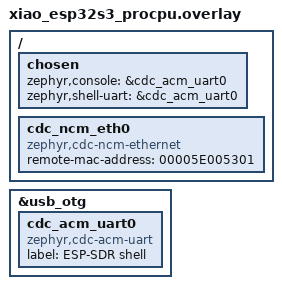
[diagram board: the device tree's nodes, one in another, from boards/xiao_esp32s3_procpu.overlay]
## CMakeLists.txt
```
# SPDX-License-Identifier: GPL-3.0-or-later

cmake_minimum_required(VERSION 3.20.0)

find_package(Zephyr REQUIRED HINTS $ENV{ZEPHYR_BASE})
project(esp_stream)

include(${CMAKE_CURRENT_LIST_DIR}/../common/common.cmake)

target_sources(app PRIVATE
  src/main.c
  src/vrt_rx.c
  src/iq_pack.c)
target_sources_ifdef(CONFIG_SHELL app PRIVATE src/shell.c)
target_sources_ifdef(CONFIG_APP_TX app PRIVATE src/vrt_tx.c)

if(CONFIG_USBD_CDC_NCM_CLASS)
  target_sources(app PRIVATE src/transport_udp.c)
else()
  target_sources(app PRIVATE src/transport_null.c)
endif()
# Per-sample loops on the stream's critical path.
set_source_files_properties(src/iq_pack.c PROPERTIES COMPILE_OPTIONS -O3)
```

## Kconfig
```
# SPDX-License-Identifier: GPL-3.0-or-later

mainmenu "ESP-SDR stream"

config APP_SDR
	bool "Run the radio"
	default y
	help
	  Disable to bring up USB and the network alone: the app then sends
	  one small test datagram per second instead of capturing.

config APP_FREQ_MHZ
	int "LO frequency in MHz at boot (shared by RX and TX)"
	range 100 6000
	default 2412

config APP_RX_RATE
	int "Capture rate (enum esp_sdr_rate index)"
	range 0 6
	default 6
	help
	  0: 80 MS/s, 1: 40 MS/s, 6: 16 MS/s. A VITA command can switch to
	  this rate divided by an integer (decimated stream).

config APP_RX_BURST_SAMPLES
	int "Complex samples per burst"
	range 256 16380
	default 1404
	help
	  Raw bursts at the capture rate, and the most a decimated burst may
	  hold. 1404 fills whole signal data packets at every item size: 3 at
	  12 bit (468 each), 2 at 8 bit (704), 4 at 16 bit (352). USB moves a
	  limited number of datagrams per second, so a part-filled packet costs
	  as much as a full one.

config APP_RX_BURSTS
	int "Burst buffers between the capture and process cores"
	default 3
	help
	  Each holds APP_RX_BURST_SAMPLES * 4 bytes, in the internal SRAM
	  above the capture bank (ESP_SDR_HIGH_RAM).

config APP_NET_CPU
	int "CPU for the network and USB threads (-1: not pinned)"
	range -1 1
	default 0
	help
	  Pins the cooperative and high priority system threads (net TX/RX
	  queues, net_mgmt, usbd, UDC, system work queue, Wi-Fi events) to
	  this CPU, the capture CPU, so they never delay the process thread or
	  the DAC leader on the other one.

config APP_RX_BURST_INTERVAL_MS
	int "Pause between bursts in ms (0: back to back)"
	default 0

config APP_RX_STREAM_ID
	hex "VITA 49 stream identifier of the receive stream"
	help
	  Command packets to this stream ID set the receiver; any other
	  stream ID addresses the transmitter.
	default 0x5d5d0001

config APP_RX_SAMPLES_PER_PACKET
	int "Complex samples per IF data packet"
	range 1 1000
	default 352
	help
	  352 samples plus six header and trailer words fit a 1500 byte
	  IPv6 UDP datagram.

config APP_RX_UDP_PEER
	string "IPv6 destination of the receive stream"
	default "ff02::1"
	help
	  The default link-local all-nodes group reaches the host without
	  any address setup on either side.

config APP_RX_UDP_PORT
	int "UDP destination port of the receive stream"
	default 4991

config APP_TX
	bool "Transmit VITA 49.2 signal data from the host"
	default y
	select ESP_SDR_TX
	help
	  Signal data and command packets on UDP; samples go to the
	  esp_sdr_tx streaming backend (the DAC backend with
	  CONFIG_ESP_SDR_TX_DAC, else the stub).

config APP_TX_UDP_PORT
	int "UDP port for transmit and command packets"
	default 4992
	depends on APP_TX

config APP_TX_RATE
	int "Transmit sample rate until a command sets one"
	default 100000
	depends on APP_TX

rsource "../common/Kconfig"

# USB device helpers shared with the in-tree USB samples.
source "samples/subsys/usb/common/Kconfig.sample_usbd"

source "Kconfig.zephyr"
```

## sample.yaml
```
sample:
  name: ESP-SDR stream
  description: >-
    Burst I/Q capture on both cores, VITA 49.2 packets as UDP over IPv6 on a
    USB CDC-NCM link, USB DFU through MCUboot, Zephyr shell on USB CDC-ACM
common:
  tags: esp-sdr
  sysbuild: true
  platform_allow:
    - xiao_esp32s3/esp32s3/procpu
  integration_platforms:
    - xiao_esp32s3/esp32s3/procpu
tests:
  # The console is on USB CDC-ACM, which twister cannot reach over
  # USB-Serial-JTAG: run it with tools/vrt_rx.py instead (see README).
  sample.esp_sdr.stream:
    build_only: true
```

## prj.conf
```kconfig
# The Wi-Fi driver brings the radio up at boot; nothing may scan or connect.
CONFIG_NETWORKING=y
CONFIG_WIFI=y
CONFIG_ESP32_WIFI_STA_POWER_SAVE_NONE=y

CONFIG_ESP_SDR=y
# Deferred logging: immediate mode formats on the caller's stack, which
# overflows the small USB driver thread stacks.
CONFIG_LOG=y
CONFIG_LOG_MODE_DEFERRED=y

# Float statistics on the process thread.
CONFIG_FPU=y
CONFIG_FPU_SHARING=y
CONFIG_PICOLIBC_IO_FLOAT=y
CONFIG_MAIN_STACK_SIZE=2048

# Capture on CPU 0 next to the Wi-Fi task, process on CPU 1.
CONFIG_SMP=y

CONFIG_LIBVRT=y

# USB device on the OTG port (DFU with sysbuild/MCUboot).
CONFIG_USB_DEVICE_STACK_NEXT=y
CONFIG_SAMPLE_USBD_PRODUCT="ESP-SDR"
CONFIG_SAMPLE_USBD_PID=0x0005
CONFIG_USBD_LOG_LEVEL_WRN=y
CONFIG_UDC_DRIVER_LOG_LEVEL_WRN=y
CONFIG_USBD_THREAD_STACK_SIZE=2048
CONFIG_UDC_DWC2_STACK_SIZE=1280

# USB network (CDC-NCM) carrying the VRT stream as UDP over IPv6.
CONFIG_USBD_CDC_NCM_CLASS=y
# Room for 5 full datagrams per OUT NTB: the host aggregates them into one
# transfer (USB full speed moves a limited number of transfers per second).
CONFIG_USBD_CDC_NCM_RECV_NTB_MAX_SIZE=8192
CONFIG_USBD_CDC_NCM_MAX_DGRAM_PER_NTB=5
# Uplink: up to 3 datagrams per IN NTB, collected while one is in flight.
CONFIG_USBD_CDC_NCM_SEND_NTB_MAX_SIZE=4608
CONFIG_USBD_CDC_NCM_SEND_MAX_DGRAM_PER_NTB=3
CONFIG_NET_IPV6=y
CONFIG_NET_IPV4=n
CONFIG_NET_UDP=y
CONFIG_NET_SOCKETS=y
# Receive timeout for the transmit socket (idle stop).
CONFIG_NET_CONTEXT_RCVTIMEO=y
CONFIG_NET_IF_MAX_IPV6_COUNT=2
CONFIG_NET_BUF_DATA_SIZE=256
CONFIG_NET_PKT_TX_COUNT=24
CONFIG_NET_BUF_TX_COUNT=32
# Receive buffers for the host's transmit stream (1500 byte datagrams).
CONFIG_NET_PKT_RX_COUNT=16
CONFIG_NET_BUF_RX_COUNT=48
# "net stats" in the shell.
CONFIG_NET_STATISTICS=y
CONFIG_NET_STATISTICS_PER_INTERFACE=y

# Console and Zephyr shell on a USB CDC-ACM port; the shell log backend
# carries the logs, so the UART backend would only duplicate them.
CONFIG_USBD_CDC_ACM_CLASS=y
# CDC-ACM carries the console and the shell: its own logging must stay off (it would log to
# itself), which usbd_cdc_acm.c otherwise enforces with a #warning that -Werror makes fatal.
CONFIG_USBD_CDC_ACM_LOG_LEVEL_OFF=y
CONFIG_CDC_ACM_SERIAL_INITIALIZE_AT_BOOT=n
CONFIG_SHELL=y
CONFIG_KERNEL_SHELL=y
CONFIG_NET_SHELL=y
CONFIG_LOG_BACKEND_UART=n
# Lean shell: net, kernel and mcuboot commands only.
CONFIG_SHELL_STACK_SIZE=3072
CONFIG_SHELL_CMD_BUFF_SIZE=128
CONFIG_SHELL_HISTORY=n
CONFIG_SHELL_WILDCARD=n
CONFIG_SHELL_BACKEND_SERIAL_LOG_MESSAGE_QUEUE_SIZE=256
CONFIG_DEVICE_SHELL=n
CONFIG_DATE_SHELL=n
CONFIG_DEVMEM_SHELL=n
# Wi-Fi management commands would also retune the radio under the receiver.
CONFIG_NET_L2_WIFI_SHELL=n

# 8 MB octal PSRAM: transmit waveform ring (EXT_RAM_BSS_ATTR).
CONFIG_ESP_SPIRAM=y
CONFIG_SPIRAM_MODE_OCT=y

# Heap statistics for `sdr mem` (sizing internal RAM).
CONFIG_SYS_HEAP_RUNTIME_STATS=y

# Internal RAM diet: two 64 KiB dump banks must fit (capture and DAC ping-pong).
# Sizes from `sdr mem` and `kernel thread stacks` after a TX and RX run.
CONFIG_ESP_WIFI_HEAP_SPIRAM=y
CONFIG_ESP32_WIFI_STATIC_RX_BUFFER_NUM=4
CONFIG_ESP32_WIFI_MGMT_SBUF_NUM=8
CONFIG_ESP32_WIFI_EVENT_TASK_STACK_SIZE=1024
CONFIG_NET_MGMT_EVENT_STACK_SIZE=1024
CONFIG_APP_RX_BURSTS=2
CONFIG_ESP_SDR_TX_DAC_STACK_SIZE=1024
# Internal system heap: peak 15.5 KB measured with the Wi-Fi heap in PSRAM.
CONFIG_HEAP_MEM_POOL_IGNORE_MIN=y
CONFIG_HEAP_MEM_POOL_SIZE=20480
```

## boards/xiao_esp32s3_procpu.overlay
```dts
/*
 * SPDX-License-Identifier: GPL-3.0-or-later
 */

/ {
	chosen {
		zephyr,console = &cdc_acm_uart0;
		zephyr,shell-uart = &cdc_acm_uart0;
	};

	/* USB network function; the host side of the link gets MAC 00:00:5e:00:53:01. */
	cdc_ncm_eth0: cdc_ncm_eth0 {
		compatible = "zephyr,cdc-ncm-ethernet";
		remote-mac-address = "00005E005301";
	};
};

zephyr_udc0: &usb_otg {
	status = "okay";

	/* Console, shell and logs while OTG owns the USB port. */
	cdc_acm_uart0: cdc_acm_uart0 {
		compatible = "zephyr,cdc-acm-uart";
		label = "ESP-SDR shell";
	};
};
```

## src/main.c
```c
/*
 * SPDX-License-Identifier: GPL-3.0-or-later
 *
 * Burst I/Q pipeline across both cores: CPU 0 captures, CPU 1 processes.
 */

#include <math.h>
#include <string.h>

#include <zephyr/app_version.h>
#include <zephyr/kernel.h>
#include <zephyr/logging/log.h>
#include <zephyr/sys/util.h>

#include <esp_sdr/esp_sdr.h>

#include "vrt_rx.h"
#include "transport.h"
#include "vrt_tx.h"
#include "app_cpu.h"
#include "app_usb.h"

LOG_MODULE_REGISTER(stream, LOG_LEVEL_INF);

#define CAPTURE_CPU 0
#define PROCESS_CPU 1
#define CAPTURE_STACK_SIZE 2048
#define PROCESS_STACK_SIZE 3072

/* Bursts live above the capture bank: frees low DRAM for the USB buffers. */
K_MEM_SLAB_DEFINE_IN_SECT(burst_slab, Z_GENERIC_SECTION(.esp_sdr_high), sizeof(struct vrt_rx_burst),
			  CONFIG_APP_RX_BURSTS, 4);
K_MSGQ_DEFINE(burst_q, sizeof(struct vrt_rx_burst *), CONFIG_APP_RX_BURSTS, 4);

K_THREAD_STACK_DEFINE(capture_stack, CAPTURE_STACK_SIZE);
K_THREAD_STACK_DEFINE(process_stack, PROCESS_STACK_SIZE);
static struct k_thread capture_thread, process_thread;

static atomic_t capture_cpu = ATOMIC_INIT(-1), process_cpu = ATOMIC_INIT(-1);
static atomic_t stalls;
/* Decimation factor, 1 = raw bursts at the capture rate. */
static atomic_t rx_decim = ATOMIC_INIT(1);
/* Algorithm used when rx_decim > 1. */
static atomic_t rx_mode = ATOMIC_INIT(VRT_RX_DECIM_CIC);

/* Decimated bursts must fit the burst buffer. */
BUILD_ASSERT(ESP_SDR_SAMPLES_MAX / VRT_RX_DECIM_MIN <= CONFIG_APP_RX_BURST_SAMPLES + 3U);
BUILD_ASSERT(sizeof(struct esp_sdr_iq16) == sizeof(struct esp_sdr_iq16));

int vrt_rx_set_rate(uint32_t hz)
{
	uint32_t fs = esp_sdr_rx_rate_hz(CONFIG_APP_RX_RATE), m;

	if (hz == 0U || fs % hz != 0U) {
		return -EINVAL;
	}
	m = fs / hz;
	if (m != 1U && (m < VRT_RX_DECIM_MIN || m > ESP_SDR_RX_DECIM_MAX)) {
		return -EINVAL;
	}
	atomic_set(&rx_decim, (atomic_val_t)m);
	return 0;
}

uint32_t vrt_rx_get_rate(void)
{
	return esp_sdr_rx_rate_hz(CONFIG_APP_RX_RATE) / (uint32_t)atomic_get(&rx_decim);
}

int vrt_rx_set_decim(enum vrt_rx_decim mode)
{
	if (mode != VRT_RX_DECIM_CIC && mode != VRT_RX_DECIM_FOLD) {
		return -EINVAL;
	}
	atomic_set(&rx_mode, (atomic_val_t)mode);
	return 0;
}

enum vrt_rx_decim vrt_rx_get_decim(void)
{
	return (enum vrt_rx_decim)atomic_get(&rx_mode);
}

static void capture(void *p1, void *p2, void *p3)
{
	enum esp_sdr_rate rate = CONFIG_APP_RX_RATE;
	uint32_t seq = 0;
	int ret;

	ARG_UNUSED(p1);
	ARG_UNUSED(p2);
	ARG_UNUSED(p3);

	ret = esp_sdr_init();
	if (ret == 0) {
		ret = esp_sdr_set_freq(CONFIG_APP_FREQ_MHZ);
	}
	if (ret != 0) {
		LOG_ERR("radio setup failed (%d)", ret);
		return;
	}

	for (;;) {
		struct vrt_rx_burst *b;

		if (k_mem_slab_alloc(&burst_slab, (void **)&b, K_NO_WAIT) != 0) {
			/* Process side is behind: wait, which also lets it run on one CPU. */
			atomic_inc(&stalls);
			(void)k_mem_slab_alloc(&burst_slab, (void **)&b, K_FOREVER);
		}
		uint32_t m = (uint32_t)atomic_get(&rx_decim);

		if (m > 1U) {
			/* Whole bank, decimated on the capture core while it still holds the bank. */
			enum vrt_rx_decim mode = (enum vrt_rx_decim)atomic_get(&rx_mode);
			size_t n;
			uint64_t first;

			if (mode == VRT_RX_DECIM_FOLD) {
				ret = esp_sdr_rx_capture_folded(rate, ESP_SDR_SAMPLES_MAX / m * m,
								 m, (struct esp_sdr_iq16 *)b->iq,
								 ARRAY_SIZE(b->iq), &n, &first);
				b->full_scale = 512;
			} else {
				ret = esp_sdr_rx_capture_decimated(rate, ESP_SDR_SAMPLES_MAX / m * m,
								    m, (struct esp_sdr_iq16 *)b->iq,
								    ARRAY_SIZE(b->iq), &n, &first);
				b->full_scale = 32768;
			}
			b->count = n;
			b->timestamp_ns = first;
			b->rate_hz = esp_sdr_rx_rate_hz(rate) / m;
		} else {
			uint64_t first;

			/* Converted under the radio lock: a TX session reuses the bank. */
			ret = esp_sdr_rx_capture_iq(rate, CONFIG_APP_RX_BURST_SAMPLES,
						    (struct esp_sdr_iq16 *)b->iq, &first);
			if (ret == 0) {
				b->count = CONFIG_APP_RX_BURST_SAMPLES;
				/* The engine starts on the trigger: arming time is the first sample. */
				b->timestamp_ns = first;
				b->rate_hz = esp_sdr_rx_rate_hz(rate);
				b->full_scale = 512;
			}
		}
		if (ret != 0) {
			LOG_WRN("capture failed (%d)", ret);
			k_mem_slab_free(&burst_slab, b);
			k_sleep(K_MSEC(100));
			continue;
		}
		b->seq = seq++;
		b->freq_mhz = esp_sdr_get_freq();
		b->gain = esp_sdr_rx_get_gain();
		atomic_set(&capture_cpu, arch_curr_cpu()->id);
		k_msgq_put(&burst_q, &b, K_FOREVER);

		if (CONFIG_APP_RX_BURST_INTERVAL_MS > 0) {
			k_sleep(K_MSEC(CONFIG_APP_RX_BURST_INTERVAL_MS));
		}
	}
}


static void process(void *p1, void *p2, void *p3)
{
	uint32_t bursts = 0, samples = 0;
	int64_t window_start = k_uptime_get();
	float power = 0.0f;

	ARG_UNUSED(p1);
	ARG_UNUSED(p2);
	ARG_UNUSED(p3);

	for (;;) {
		struct vrt_rx_burst *b;
		uint64_t sum = 0;
		int64_t now;

		k_msgq_get(&burst_q, &b, K_FOREVER);
		atomic_set(&process_cpu, arch_curr_cpu()->id);

		/* Integer energy: at most 2 * 32768^2 per sample, fits 32 bits unsigned. */
		for (size_t j = 0; j < b->count; j++) {
			int32_t i = b->iq[j].i, q = b->iq[j].q;

			sum += (uint32_t)(i * i) + (uint32_t)(q * q);
		}
		power = (float)sum / (float)b->count /
			((float)b->full_scale * (float)b->full_scale);
		vrt_rx_burst(b);
		bursts++;
		samples += b->count;
		k_mem_slab_free(&burst_slab, b);

		now = k_uptime_get();
		if (now - window_start >= 1000) {
			float secs = (float)(now - window_start) / 1000.0f;

			LOG_DBG("capture cpu %ld, process cpu %ld, %u bursts/s, "
				"%.2f MS/s, %.1f dBFS, stalls %ld",
				atomic_get(&capture_cpu), atomic_get(&process_cpu),
				(unsigned int)((float)bursts / secs),
				(double)((float)samples / secs / 1e6f),
				(double)(10.0f * log10f(MAX(power, 1e-12f))), atomic_get(&stalls));
			vrt_rx_report();
			bursts = 0;
			samples = 0;
			window_start = now;
		}
	}
}

int main(void)
{
	printk("stream %s\n", APP_VERSION_STRING);
	LOG_INF("cpus %u, %u MHz, %u-sample bursts", arch_num_cpus(), CONFIG_APP_FREQ_MHZ,
		CONFIG_APP_RX_BURST_SAMPLES);

#if defined(CONFIG_SCHED_CPU_MASK) && CONFIG_APP_NET_CPU >= 0
	/*
	 * Before USB starts: its bring-up runs on the system work queue, and
	 * the controller interrupt lands on the CPU that allocates it.
	 */
	if (arch_num_cpus() > 1) {
		app_cpu_pin_system_threads(CONFIG_APP_NET_CPU);
	}
#endif
	if (app_usb_init() != 0) {
		LOG_ERR("usb init failed");
	}
	if (vrt_rx_init() != 0) {
		LOG_ERR("stream init failed");
		return 0;
	}
	if (IS_ENABLED(CONFIG_APP_TX) && vrt_tx_init() != 0) {
		LOG_ERR("tx init failed");
	}

	if (!IS_ENABLED(CONFIG_APP_SDR)) {
		/* USB bring-up test: a small datagram per second instead of samples. */
		static const char beacon[] = "rx stream: beacon\n";

		for (;;) {
			(void)transport_send(beacon, sizeof(beacon) - 1);
			k_sleep(K_SECONDS(1));
		}
	}

	k_thread_create(&capture_thread, capture_stack, K_THREAD_STACK_SIZEOF(capture_stack),
			capture, NULL, NULL, NULL, K_PRIO_PREEMPT(5), 0, K_FOREVER);
	k_thread_create(&process_thread, process_stack, K_THREAD_STACK_SIZEOF(process_stack),
			process, NULL, NULL, NULL, K_PRIO_PREEMPT(6), 0, K_FOREVER);
	k_thread_name_set(&capture_thread, "rx_capture");
	k_thread_name_set(&process_thread, "rx_process");
#if defined(CONFIG_SCHED_CPU_MASK)
	if (arch_num_cpus() > 1) {
		k_thread_cpu_pin(&capture_thread, CAPTURE_CPU);
		k_thread_cpu_pin(&process_thread, PROCESS_CPU);
#if CONFIG_APP_NET_CPU >= 0
		/* Again for the threads started since (usbd, UDC). */
		app_cpu_pin_system_threads(CONFIG_APP_NET_CPU);
#endif
	}
#endif
	k_thread_start(&capture_thread);
	k_thread_start(&process_thread);
	return 0;
}
```

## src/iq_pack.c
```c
/*
 * SPDX-License-Identifier: GPL-3.0-or-later
 */

#include <zephyr/sys/util.h>

#include "iq_pack.h"

size_t iq_samples_per_words(unsigned int bits, size_t max_words)
{
	size_t n = max_words * 32U / (2U * bits);

	return n - n % iq_sample_quantum(bits);
}

/* Item of `bits` from a sample: scaled by 2^-shift (rounded) or 2^shift, saturated. */
static inline uint32_t item(int32_t x, int32_t shift, int32_t lim, uint32_t mask)
{
	if (shift > 0) {
		x = (x + (1 << (shift - 1))) >> shift;
	} else {
		x <<= -shift;
	}
	return (uint32_t)CLAMP(x, -lim, lim - 1) & mask;
}

size_t iq_pack(const struct esp_sdr_iq16 *s, size_t n, unsigned int bits, int32_t full_scale,
	       uint32_t *words)
{
	int32_t lim = 1 << (bits - 1U);
	uint32_t mask = (1U << bits) - 1U;
	/* full_scale is a power of two: 512 (raw) or 32768 (decimated). */
	int32_t shift = (int32_t)(31 - __builtin_clz((uint32_t)full_scale)) - (int32_t)(bits - 1U);
	uint64_t acc = 0;
	unsigned int have = 0;
	size_t w = 0, j = 0;

	if (bits == 16U) {
		/* Legacy layout: native scale, I in the upper half word. */
		for (; j < n; j++) {
			words[j] = ((uint32_t)(uint16_t)s[j].i << 16) | (uint16_t)s[j].q;
		}
		return n;
	}
	if (bits == 8U) {
		/* Two samples per word. */
		for (; j + 2U <= n; j += 2U) {
			words[w++] = item(s[j].i, shift, lim, mask) << 24 |
				     item(s[j].q, shift, lim, mask) << 16 |
				     item(s[j + 1U].i, shift, lim, mask) << 8 |
				     item(s[j + 1U].q, shift, lim, mask);
		}
	} else if (bits == 12U) {
		/* Four samples, eight items, in three words. */
		for (; j + 4U <= n; j += 4U) {
			uint32_t a = item(s[j].i, shift, lim, mask), b = item(s[j].q, shift, lim, mask);
			uint32_t c = item(s[j + 1U].i, shift, lim, mask);
			uint32_t d = item(s[j + 1U].q, shift, lim, mask);
			uint32_t e = item(s[j + 2U].i, shift, lim, mask);
			uint32_t f = item(s[j + 2U].q, shift, lim, mask);
			uint32_t g = item(s[j + 3U].i, shift, lim, mask);
			uint32_t h = item(s[j + 3U].q, shift, lim, mask);

			words[w++] = a << 20 | b << 8 | c >> 4;
			words[w++] = c << 28 | d << 16 | e << 4 | f >> 8;
			words[w++] = f << 24 | g << 12 | h;
		}
	}
	/* Whatever is left (none in whole quanta), MSB first. */
	for (; j < n; j++) {
		acc = (acc << (2U * bits)) | ((uint64_t)item(s[j].i, shift, lim, mask) << bits) |
		      item(s[j].q, shift, lim, mask);
		have += 2U * bits;
		while (have >= 32U) {
			have -= 32U;
			words[w++] = (uint32_t)(acc >> have);
		}
	}
	if (have > 0U) {
		/* Left aligned, zero padded (less than one item thanks to the quantum). */
		words[w++] = (uint32_t)(acc << (32U - have));
	}
	return w;
}

size_t iq_unpack(const uint32_t *words, size_t nwords, unsigned int bits, int16_t *iq,
		 size_t max)
{
	uint64_t acc = 0;
	unsigned int have = 0;
	size_t n = 0;

	if (bits == 16U) {
		for (; n < nwords && n < max; n++) {
			iq[2U * n] = (int16_t)(words[n] >> 16);
			iq[2U * n + 1U] = (int16_t)(words[n] & 0xffffU);
		}
		return n;
	}
	for (size_t k = 0; k < nwords && n < max; k++) {
		acc = (acc << 32) | words[k];
		have += 32U;
		while (have >= 2U * bits && n < max) {
			uint32_t pair = (uint32_t)(acc >> (have - 2U * bits));

			have -= 2U * bits;
			/* Item to the top of 32 bits (sign there), down 16: int16 full scale. */
			iq[2U * n] = (int16_t)((int32_t)((pair >> bits) << (32U - bits)) >> 16);
			iq[2U * n + 1U] = (int16_t)((int32_t)(pair << (32U - bits)) >> 16);
			n++;
		}
	}
	return n;
}
```

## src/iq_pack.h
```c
/*
 * SPDX-License-Identifier: GPL-3.0-or-later
 *
 * VITA 49 link-efficient complex payloads: I then Q per sample, 8, 12 or 16
 * bits per item, packed MSB first across 32-bit words (CPU order; the stream
 * code swaps to network order).
 */

#ifndef STREAM_IQ_PACK_H_
#define STREAM_IQ_PACK_H_

#include <stddef.h>
#include <stdint.h>

#include "vrt_rx.h"

/* Supported item sizes. */
static inline int iq_bits_valid(unsigned int bits)
{
	return bits == 8U || bits == 12U || bits == 16U;
}

/*
 * Samples per packet must fill whole words without a padding gap a whole item
 * wide, or the receiver would see a phantom sample: multiples of this.
 */
static inline size_t iq_sample_quantum(unsigned int bits)
{
	return bits == 12U ? 4U : bits == 8U ? 2U : 1U;
}

/* Most samples (a whole quantum) that fit max_words. */
size_t iq_samples_per_words(unsigned int bits, size_t max_words);

/*
 * Pack n samples into words. 16-bit items keep the stream's own scale (full
 * scale 512 raw, 32768 decimated); 8 and 12-bit items are scaled to their own
 * full scale (2^(bits-1)), rounded and saturated. Returns words written.
 */
size_t iq_pack(const struct esp_sdr_iq16 *s, size_t n, unsigned int bits, int32_t full_scale,
	       uint32_t *words);

/*
 * Unpack nwords into interleaved int16 I, Q (8 and 12-bit items shifted up to
 * full scale 32767, 16-bit items as they are); returns samples written, at
 * most max.
 */
size_t iq_unpack(const uint32_t *words, size_t nwords, unsigned int bits, int16_t *iq,
		 size_t max);

#endif /* STREAM_IQ_PACK_H_ */
```

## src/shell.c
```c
/*
 * SPDX-License-Identifier: GPL-3.0-or-later
 *
 * The "sdr" shell command: receiver and transmitter controls and tests. The
 * receive stream picks changes up per burst.
 */

#include <math.h>
#include <stdlib.h>
#include <string.h>

#include <zephyr/kernel.h>
#include <zephyr/shell/shell.h>
#include <zephyr/sys/sys_heap.h>

#include <esp_attr.h>

#include <esp_sdr/esp_sdr.h>

#include "vrt_rx.h"

#if defined(CONFIG_APP_TX)
#include <esp_sdr/esp_sdr_tx.h>

#include "vrt_tx.h"
#endif

extern struct k_heap _system_heap;

static int cmd_mem(const struct shell *sh, size_t argc, char **argv)
{
	struct sys_memory_stats st;

	ARG_UNUSED(argc);
	ARG_UNUSED(argv);
	if (sys_heap_runtime_stats_get(&_system_heap.heap, &st) != 0) {
		shell_error(sh, "no heap stats");
		return -EIO;
	}
	shell_print(sh, "system heap: %u allocated, %u free, %u peak",
		    (unsigned int)st.allocated_bytes, (unsigned int)st.free_bytes,
		    (unsigned int)st.max_allocated_bytes);
	return 0;
}

#if defined(CONFIG_APP_TX)


/*
 * Transmit synthesis. The DAC runs at its own rate (40 or 80 MS/s, never the
 * 16 MS/s the receiver uses), so every generator works in Hz and seconds and
 * converts with esp_sdr_tx_rate_hz(). One buffer serves all of them.
 */
#define TX_RATE        ESP_SDR_RATE_40MSPS
#define TX_BUF_SAMPLES 2048U /* 51 us at 40 MS/s; RAM below the capture bank is tight */
#define FM_TWO_PI      6.28318530717958647692
#define FM_TWO_PI_F    6.28318530717958647692f
/* PSRAM: only CPU copies read it, the DAC plays from the bank. */
static EXT_RAM_BSS_ATTR uint32_t tx_buf[TX_BUF_SAMPLES];

static enum esp_sdr_rate tx_rate_arg(size_t argc, char **argv, size_t idx)
{
	return argc > idx ? (enum esp_sdr_rate)strtol(argv[idx], NULL, 0) : TX_RATE;
}

static int cmd_fm(const struct shell *sh, size_t argc, char **argv)
{
	double fm_hz = strtod(argv[1], NULL);
	double dev_hz = strtod(argv[2], NULL);
	long amp = argc > 3 ? strtol(argv[3], NULL, 0) : 400;
	double fs = (double)esp_sdr_tx_rate_hz(TX_RATE);
	double phase = 0.0;
	int ret;

	if (amp <= 0 || amp > 511) {
		shell_error(sh, "amplitude must be 1..511");
		return -EINVAL;
	}

	/* Instantaneous offset dev_hz * sin(2 pi fm_hz t), integrated to phase. */
	for (size_t n = 0; n < TX_BUF_SAMPLES; n++) {
		double inst_hz = dev_hz * sin(FM_TWO_PI * fm_hz * (double)n / fs);

		phase += FM_TWO_PI * inst_hz / fs;
		tx_buf[n] = esp_sdr_tx_word((int16_t)lround((double)amp * cos(phase)),
					    (int16_t)lround((double)amp * sin(phase)));
	}

	ret = esp_sdr_tx_play(TX_RATE, tx_buf, TX_BUF_SAMPLES);
	if (ret != 0) {
		shell_error(sh, "play: %d", ret);
		return ret;
	}
	shell_print(sh, "played %u samples at %u MS/s, %u MHz, fm %.1f Hz dev %.1f Hz amp %ld",
		    TX_BUF_SAMPLES, (unsigned int)(fs / 1e6), esp_sdr_get_freq(), fm_hz, dev_hz,
		    amp);
	return 0;
}

/*
 * Period length for a seamless tone: the n in [MIN, TX_BUF_SAMPLES] whose
 * whole number of cycles comes closest to the requested frequency.
 */
static size_t tone_period(double req, double fs, long *cycles)
{
	size_t best_n = TX_BUF_SAMPLES;
	double best_err = INFINITY;

	for (size_t n = TX_BUF_SAMPLES; n >= ESP_SDR_SAMPLES_MIN; n--) {
		long c = lround(req * (double)n / fs);
		double err = fabs((double)c * fs / (double)n - req);

		if (err < best_err) {
			best_err = err;
			best_n = n;
			*cycles = c;
			if (err < 1.0) {
				break;
			}
		}
	}
	return best_n;
}

/*
 * Quick link check: a steady tone (no modulation) and a one-shot receiver
 * that reports average power and average frequency over a whole burst, with
 * no search loop. Use this before fsktx/fskrx to confirm TX actually
 * reaches the other board at a sane level and offset.
 */
static int cmd_tonetx(const struct shell *sh, size_t argc, char **argv)
{
	double req = argc > 1 ? strtod(argv[1], NULL) : 1000000.0;
	uint32_t ms = argc > 2 ? (uint32_t)strtoul(argv[2], NULL, 0) : 0U;
	long amp = argc > 3 ? strtol(argv[3], NULL, 0) : 511;
	enum esp_sdr_rate rate = tx_rate_arg(argc, argv, 4);
	double fs = (double)esp_sdr_tx_rate_hz(rate);
	uint32_t bursts = 0;
	long cycles = 0;
	size_t n;
	int ret;

	if (fs == 0.0) {
		shell_error(sh, "transmit rate index must be 0 (80 MS/s) or 1 (40 MS/s)");
		return -EINVAL;
	}
	if (amp <= 0 || amp > 511 || fabs(req) >= fs / 2.0) {
		shell_error(sh, "amplitude must be 1..511 and |hz| below %.0f", fs / 2.0);
		return -EINVAL;
	}
	n = tone_period(req, fs, &cycles);
	for (size_t k = 0; k < n; k++) {
		double phase = FM_TWO_PI * (double)cycles * (double)k / (double)n;

		tx_buf[k] = esp_sdr_tx_word((int16_t)lround((double)amp * cos(phase)),
					    (int16_t)lround((double)amp * sin(phase)));
	}
	ret = esp_sdr_tx_play_for(rate, tx_buf, n, ms, &bursts);
	if (ret != 0) {
		shell_error(sh, "play: %d", ret);
		return ret;
	}
	shell_print(sh,
		    "tonetx: %u MHz %+.0f Hz, %u MS/s, period %u, amp %ld, txgain %d, %u bursts in %u ms",
		    esp_sdr_get_freq(), (double)cycles * fs / (double)n, (unsigned int)(fs / 1e6),
		    (unsigned int)n, amp, esp_sdr_tx_get_gain(), bursts, ms);
	return 0;
}

static int cmd_sweep(const struct shell *sh, size_t argc, char **argv)
{
	float f0 = strtof(argv[1], NULL), f1 = strtof(argv[2], NULL);
	uint32_t ms = (uint32_t)strtoul(argv[3], NULL, 0);
	int amp = argc > 4 ? (int)strtol(argv[4], NULL, 0) : 256;
	enum esp_sdr_rate rate = tx_rate_arg(argc, argv, 5);
	struct esp_sdr_tx_sweep_stats st;
	int ret = esp_sdr_tx_sweep(rate, f0, f1, ms, amp, &st);
	double fs = (double)esp_sdr_tx_rate_hz(rate);

	if (ret != 0) {
		shell_error(sh, "sweep: %d (|hz| below rate/2, ms 1..%u, amp 1..511)", ret,
			    ESP_SDR_TX_PLAY_MAX_MS);
		return ret;
	}
	shell_print(sh,
		    "sweep: %+.0f -> %+.0f Hz in %u ms at %u MS/s, txgain %d, amp %d: %u segments, "
		    "%u samples, duty %.0f %%",
		    (double)f0, (double)f1, st.elapsed_ms, (unsigned int)(fs / 1e6),
		    esp_sdr_tx_get_gain(), amp, st.segments, st.samples,
		    100.0 * st.samples / fs / (st.elapsed_ms / 1e3));
	return 0;
}

static int cmd_tonerx(const struct shell *sh, size_t argc, char **argv)
{
	struct esp_sdr_rx_burst b;
	float fs = (float)esp_sdr_rx_rate_hz(ESP_SDR_RATE_16MSPS);
	float sum_sq = 0.0f, sum_delta = 0.0f;
	int ret;

	ARG_UNUSED(argc);
	ARG_UNUSED(argv);

	ret = esp_sdr_rx_capture(ESP_SDR_RATE_16MSPS, ESP_SDR_SAMPLES_MAX, &b);
	if (ret != 0) {
		shell_error(sh, "capture: %d", ret);
		return ret;
	}
	for (size_t n = 0; n < b.count; n++) {
		float i = (float)esp_sdr_rx_i(b.words[n]), q = (float)esp_sdr_rx_q(b.words[n]);

		sum_sq += i * i + q * q;
	}
	for (size_t n = 1; n < b.count; n++) {
		float i0 = (float)esp_sdr_rx_i(b.words[n - 1]), q0 = (float)esp_sdr_rx_q(b.words[n - 1]);
		float i1 = (float)esp_sdr_rx_i(b.words[n]), q1 = (float)esp_sdr_rx_q(b.words[n]);
		float cross = q1 * i0 - i1 * q0, dot = i1 * i0 + q1 * q0;

		sum_delta += atan2f(cross, dot);
	}

	float power_dbfs = 10.0f * log10f(MAX(sum_sq / (float)b.count / (512.0f * 512.0f), 1e-12f));
	float avg_freq = sum_delta / (float)(b.count - 1) * fs / (float)FM_TWO_PI;

	shell_print(sh, "tonerx: %u samples, %.1f dBFS, avg freq %+.0f Hz", (unsigned int)b.count,
		    (double)power_dbfs, (double)avg_freq);
	return 0;
}

/*
 * Minimal 2-FSK: one bit is FSK_BIT_US of a continuous-phase tone at
 * +-FSK_DEV_HZ from the tuned LO. Frame: 0xAA preamble byte (for bit-timing
 * search on receive), a length byte, then up to FSK_MAX_MSG message bytes,
 * all MSB first. No error correction and no CRC: this is a demo of the
 * modulation and of differential-phase demodulation, not a protocol.
 * The whole frame must fit tx_buf at the transmit rate, hence the short bits.
 */
#define FSK_BIT_US     2U  /* 500 kbit/s */
#define FSK_SPB        32U /* receive samples per bit: FSK_BIT_US at 16 MS/s */
#define FSK_DEV_HZ     200000.0f
#define FSK_PREAMBLE   0xAAU
#define FSK_MAX_MSG    3U
#define FSK_MAX_BITS   ((2U + FSK_MAX_MSG) * 8U)
#define FSK_SEARCH_STEP 8U
/* No shared clock between boards: keep capturing bursts for this long so an
 * independently, manually triggered sdr fsktx has a real chance of landing
 * inside the window instead of between two 1 ms-ish captures.
 */
#define FSK_RX_WINDOW_MS 4000U

static int cmd_fsktx(const struct shell *sh, size_t argc, char **argv)
{
	const char *text = argv[1];
	size_t len = strlen(text);
	uint8_t frame[2U + FSK_MAX_MSG];
	float fs = (float)esp_sdr_tx_rate_hz(TX_RATE);
	size_t spb = (size_t)(fs / 1e6f) * FSK_BIT_US;
	float phase = 0.0f;
	size_t bit = 0, nbits, nsamples;
	int ret;

	ARG_UNUSED(argc);
	if (len == 0 || len > FSK_MAX_MSG) {
		shell_error(sh, "message must be 1..%u bytes", FSK_MAX_MSG);
		return -EINVAL;
	}

	frame[0] = FSK_PREAMBLE;
	frame[1] = (uint8_t)len;
	memcpy(&frame[2], text, len);
	nbits = (2U + len) * 8U;
	nsamples = nbits * spb;
	if (nsamples > TX_BUF_SAMPLES) {
		shell_error(sh, "frame needs %u samples, buffer holds %u", (unsigned int)nsamples,
			    TX_BUF_SAMPLES);
		return -ENOMEM;
	}

	for (size_t byte = 0; byte < 2U + len; byte++) {
		for (int b = 7; b >= 0; b--, bit++) {
			float freq = ((frame[byte] >> b) & 1) ? FSK_DEV_HZ : -FSK_DEV_HZ;

			for (size_t s = 0; s < spb; s++) {
				phase += FM_TWO_PI_F * freq / fs;
				tx_buf[bit * spb + s] =
					esp_sdr_tx_word((int16_t)(400.0f * cosf(phase)),
							(int16_t)(400.0f * sinf(phase)));
			}
		}
	}

	ret = esp_sdr_tx_play(TX_RATE, tx_buf, nsamples);
	if (ret != 0) {
		shell_error(sh, "play: %d", ret);
		return ret;
	}
	shell_print(sh, "fsk tx: %u bytes ('%s'), %u bits, %u samples", (unsigned int)len, text,
		    (unsigned int)nbits, (unsigned int)nsamples);
	return 0;
}

/*
 * Instantaneous frequency of the bit starting at words[start], from the
 * phase angle between each pair of subsequent samples: delta = angle(w[n] *
 * conj(w[n-1])), computed as atan2 of the cross and dot products so there is
 * no need to unwrap a running phase.
 */
static bool fsk_bit(const uint32_t *words, size_t start)
{
	float cross_sum = 0.0f, dot_sum = 0.0f;

	/* Sum the per-sample cross/dot products first and take one atan2f of the
	 * total, instead of one atan2f per sample pair: equivalent for the small
	 * per-sample phase steps here, and ~FSK_SPB times fewer atan2f calls -
	 * that call was the search loop's real cost, not the float/double choice.
	 */
	for (size_t s = 1; s < FSK_SPB; s++) {
		size_t idx = start + s;
		float i0 = (float)esp_sdr_rx_i(words[idx - 1]), q0 = (float)esp_sdr_rx_q(words[idx - 1]);
		float i1 = (float)esp_sdr_rx_i(words[idx]), q1 = (float)esp_sdr_rx_q(words[idx]);

		cross_sum += q1 * i0 - i1 * q0;
		dot_sum += i1 * i0 + q1 * q0;
	}
	return atan2f(cross_sum, dot_sum) > 0.0f;
}

static int cmd_fskrx(const struct shell *sh, size_t argc, char **argv)
{
	int64_t t0 = k_uptime_get();
	unsigned int attempt = 0;

	ARG_UNUSED(argc);
	ARG_UNUSED(argv);

	for (; k_uptime_get() - t0 < FSK_RX_WINDOW_MS; attempt++) {
		struct esp_sdr_rx_burst b;
		size_t best_off = 0, pos;
		unsigned int best_errors = 9U;
		uint8_t len;
		char msg[FSK_MAX_MSG + 1U];

		if (esp_sdr_rx_capture(ESP_SDR_RATE_16MSPS, ESP_SDR_SAMPLES_MAX, &b) != 0) {
			continue;
		}

		/* Brute-force bit-timing search: slide a candidate start and score
		 * it against the known preamble bits.
		 */
		for (size_t off = 1; off + 8U * FSK_SPB <= b.count; off += FSK_SEARCH_STEP) {
			unsigned int errors = 0;

			for (unsigned int k = 0; k < 8U; k++) {
				bool bitval = fsk_bit(b.words, off + (size_t)k * FSK_SPB);
				bool expect = ((FSK_PREAMBLE >> (7U - k)) & 1U) != 0U;

				errors += (bitval != expect);
			}
			if (errors < best_errors) {
				best_errors = errors;
				best_off = off;
			}
		}
		if (best_errors > 1U) {
			continue; /* no preamble in this burst; try the next one */
		}

		pos = best_off + 8U * FSK_SPB;
		if (pos + 8U * FSK_SPB > b.count) {
			continue;
		}
		len = 0;
		for (unsigned int k = 0; k < 8U; k++) {
			len = (uint8_t)((len << 1) | (fsk_bit(b.words, pos + (size_t)k * FSK_SPB)
							       ? 1U
							       : 0U));
		}
		pos += 8U * FSK_SPB;
		if (len == 0U || len > FSK_MAX_MSG || pos + (size_t)len * 8U * FSK_SPB > b.count) {
			continue;
		}

		for (uint8_t byte = 0; byte < len; byte++) {
			uint8_t v = 0;

			for (unsigned int k = 0; k < 8U; k++) {
				v = (uint8_t)((v << 1) |
					      (fsk_bit(b.words, pos + (size_t)k * FSK_SPB) ? 1U
										    : 0U));
			}
			pos += 8U * FSK_SPB;
			msg[byte] = (char)v;
		}
		msg[len] = '\0';
		shell_print(sh, "fsk rx: %u bytes, %u preamble errors, attempt %u: \"%s\"",
			    (unsigned int)len, best_errors, attempt + 1, msg);
		return 0;
	}

	shell_error(sh, "fsk rx: no signal found in %u attempts (%u ms)", attempt,
		    FSK_RX_WINDOW_MS);
	return -ENOMSG;
}

#define SDR_TX_CMD                                                                                \
	SHELL_CMD_ARG(fm, NULL, "<fm_hz> <dev_hz> [amp] play one FM sine burst", cmd_fm, 3, 1),   \
	SHELL_CMD_ARG(tonetx, NULL, "[hz] [ms] [amp] [rate 0|1] tone at 80|40 MS/s, default +1 MHz",\
		      cmd_tonetx, 1, 4),                                                          \
	SHELL_CMD_ARG(sweep, NULL, "<f0_hz> <f1_hz> <ms> [amp] [rate 0|1] linear frequency sweep",\
		      cmd_sweep, 4, 2),                                                           \
	SHELL_CMD_ARG(tonerx, NULL, "one-shot capture: average power and frequency", cmd_tonerx,  \
		      1, 0),                                                                      \
	SHELL_CMD_ARG(fsktx, NULL, "<text> send one FSK frame (<=3 bytes)", cmd_fsktx, 2, 0),     \
	SHELL_CMD_ARG(fskrx, NULL, "receive one FSK frame (differential-phase demod)", cmd_fskrx, \
		      1, 0),
#else
#define SDR_TX_CMD
#endif

static int parse_long(const struct shell *sh, const char *s, long min, long max, long *out)
{
	char *end;
	long v = strtol(s, &end, 0);

	if (*s == '\0' || *end != '\0' || v < min || v > max) {
		shell_error(sh, "bad value: %s (%ld to %ld)", s, min, max);
		return -EINVAL;
	}
	*out = v;
	return 0;
}

static int set_freq(const struct shell *sh, const char *value)
{
	long mhz;

	if (parse_long(sh, value, ESP_SDR_FREQ_MIN_MHZ, ESP_SDR_FREQ_MAX_MHZ, &mhz) != 0) {
		return -EINVAL;
	}
	return esp_sdr_set_freq((uint32_t)mhz);
}

static int set_rxgain(const struct shell *sh, const char *value)
{
	long g = ESP_SDR_RX_GAIN_AUTO;

	if (strcmp(value, "auto") != 0 &&
	    parse_long(sh, value, ESP_SDR_RX_GAIN_AUTO, esp_sdr_rx_gain_max(), &g) != 0) {
		return -EINVAL;
	}
	return esp_sdr_rx_set_gain((int)g);
}

static int set_decim(const struct shell *sh, const char *value)
{
	if (strcmp(value, "cic") == 0) {
		return vrt_rx_set_decim(VRT_RX_DECIM_CIC);
	}
	if (strcmp(value, "fold") == 0) {
		return vrt_rx_set_decim(VRT_RX_DECIM_FOLD);
	}
	shell_error(sh, "decim: cic or fold");
	return -EINVAL;
}

#if defined(CONFIG_APP_TX)
static int set_txgain(const struct shell *sh, const char *value)
{
	long step;

	if (parse_long(sh, value, 0, esp_sdr_tx_gain_max(), &step) != 0) {
		return -EINVAL;
	}
	return esp_sdr_tx_set_gain((int)step);
}

static void print_tx_status(const struct shell *sh)
{
	struct esp_sdr_tx_stats bs;
	struct vrt_tx_stats st;
	uint64_t freq;
	uint32_t rate;

	vrt_tx_get_stats(&st);
	vrt_tx_get_settings(&freq, &rate);
	esp_sdr_tx_get_stats(&bs);
	shell_print(sh, "tx %s, backend %s, %llu Hz, %u S/s",
		    esp_sdr_tx_active() ? "active" : "idle", esp_sdr_tx_get_backend()->name,
		    (unsigned long long)freq, rate);
	shell_print(sh,
		    "packets %u data, %u commands, %u acks, %u gaps, %u underruns, %u bad, "
		    "%u errors; samples %u hole-filled, %u late",
		    st.data, st.commands, st.acks, st.gaps, st.underruns, st.bad, st.errors, st.holes,
		    st.late);
	shell_print(sh, "backend %llu samples in %u writes, %u errors",
		    (unsigned long long)bs.samples, bs.writes, bs.errors);
#if defined(CONFIG_ESP_SDR_TX_DAC)
	struct esp_sdr_tx_dac_stats ds;

	esp_sdr_tx_dac_get_stats(&ds);
	shell_print(sh,
		    "dac x%u: %llu played, %llu dropped (%.0f %% on air), %u switches, %u underruns, "
		    "%u overruns, %u errors, %u ms",
		    ds.interp, (unsigned long long)ds.played, (unsigned long long)ds.dropped,
		    ds.played + ds.dropped ? 100.0 * ds.played / (ds.played + ds.dropped) : 0.0,
		    ds.switches, ds.underruns, ds.overruns, ds.errors, ds.elapsed_us / 1000U);
	shell_print(sh, "dac interpolator: %s", ds.simd ? "vector (PIE)" : "C");
	shell_print(sh, "dac loop: %u switches, %u us mean apart, %u us max; slack min %d us, "
		    "%u restarts",
		    ds.switches, ds.switches > 1U ? ds.switch_us_sum / (ds.switches - 1U) : 0U,
		    ds.switch_us_max, ds.slack_us_min, ds.restarts);
	shell_print(sh, "dac leader: fill max %u us, woke late max %u us, switch-to-fill max %u us",
		    ds.fill_us_max, ds.wake_late_us_max, ds.idle_us_max);
	for (int f = 0; f < 2; f++) {
		shell_print(sh, "dac filler %d: %u blocks, %u ms filling, cpu %u", f,
			    ds.fill_blocks[f], ds.fill_us[f] / 1000U, ds.fill_cpu[f]);
	}
#endif
}

#endif

static const struct setting {
	const char *key, *help;
	int (*set)(const struct shell *sh, const char *value);
} settings[] = {
	{"freq", "<MHz>: LO, shared by receive and transmit", set_freq},
	{"rxgain", "auto|<index>: hardware AGC or a fixed gain index", set_rxgain},
	{"decim", "cic|fold: decimation below the capture rate (fold: full-band power)", set_decim},
#if defined(CONFIG_APP_TX)
	{"txgain", "<step>: transmit power step, 0 weakest", set_txgain},
#endif
};

/* set [<key> <value> ...]: settings, applied in order; without arguments the keys. */
static int cmd_set(const struct shell *sh, size_t argc, char **argv)
{
	if (argc == 1) {
		ARRAY_FOR_EACH(settings, k) {
			shell_print(sh, "  %-7s %s", settings[k].key, settings[k].help);
		}
		return 0;
	}
	if ((argc - 1U) % 2U != 0U) {
		shell_error(sh, "usage: set <key> <value> [<key> <value> ...]");
		return -EINVAL;
	}
	for (size_t a = 1; a + 1U < argc; a += 2U) {
		const struct setting *st = NULL;
		int ret;

		ARRAY_FOR_EACH(settings, k) {
			if (strcmp(argv[a], settings[k].key) == 0) {
				st = &settings[k];
			}
		}
		if (st == NULL) {
			shell_error(sh, "unknown key %s (sdr set lists them)", argv[a]);
			return -EINVAL;
		}
		ret = st->set(sh, argv[a + 1U]);
		shell_print(sh, "%s %s: %d", argv[a], argv[a + 1U], ret);
		if (ret != 0) {
			return ret;
		}
	}
	return 0;
}

/* status: receive settings, and the transmit path's state and counters. */
static int cmd_status(const struct shell *sh, size_t argc, char **argv)
{
	int gain = esp_sdr_rx_get_gain();
	const char *decim = vrt_rx_get_decim() == VRT_RX_DECIM_FOLD ? "fold" : "cic";

	ARG_UNUSED(argc);
	ARG_UNUSED(argv);
	if (gain < 0) {
		shell_print(sh, "rx: freq %u MHz, rxgain auto (max %d), decim %s, %u S/s, %u bit",
			    esp_sdr_get_freq(), esp_sdr_rx_gain_max(), decim, vrt_rx_get_rate(),
			    vrt_rx_get_bits());
	} else {
		shell_print(sh, "rx: freq %u MHz, rxgain %d (max %d), decim %s, %u S/s, %u bit",
			    esp_sdr_get_freq(), gain, esp_sdr_rx_gain_max(), decim, vrt_rx_get_rate(),
			    vrt_rx_get_bits());
	}
#if defined(CONFIG_APP_TX)
	shell_print(sh, "txgain %d (max %d, vendor target power %d)", esp_sdr_tx_get_gain(),
		    esp_sdr_tx_gain_max(), esp_sdr_tx_gain_power(esp_sdr_tx_get_gain()));
	print_tx_status(sh);
#endif
	return 0;
}

SHELL_STATIC_SUBCMD_SET_CREATE(sdr_cmds,
			       SHELL_CMD(status, NULL, "settings, transmit path state and counters",
					 cmd_status),
			       SHELL_CMD_ARG(set, NULL,
					     "[<key> <value> ...]: settings (without arguments: the keys)",
					     cmd_set, 1, 8),
			       SHELL_CMD(mem, NULL, "system heap use", cmd_mem),
			       SDR_TX_CMD SHELL_SUBCMD_SET_END);

SHELL_CMD_REGISTER(sdr, &sdr_cmds, "ESP-SDR radio", NULL);
```

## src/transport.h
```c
/*
 * SPDX-License-Identifier: GPL-3.0-or-later
 */

#ifndef STREAM_TRANSPORT_H_
#define STREAM_TRANSPORT_H_

#include <stddef.h>

int transport_init(void);
/* Send one packet; returns 0 or a negative errno. */
int transport_send(const void *buf, size_t len);
void transport_report(void);

#endif /* STREAM_TRANSPORT_H_ */
```

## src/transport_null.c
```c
/*
 * SPDX-License-Identifier: GPL-3.0-or-later
 *
 * Packet sink without a network, for measuring the encoder alone.
 */

#include "transport.h"

int transport_init(void)
{
	return 0;
}

int transport_send(const void *buf, size_t len)
{
	(void)buf;
	(void)len;
	return 0;
}

void transport_report(void)
{
}
```

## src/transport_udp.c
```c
/*
 * SPDX-License-Identifier: GPL-3.0-or-later
 *
 * VRT packets as UDP datagrams over IPv6 on the USB (CDC-NCM) interface.
 * The default peer is the link-local all-nodes group, so the host needs no
 * address setup; a unicast peer works as well.
 */

#include <errno.h>

#include <zephyr/kernel.h>
#include <zephyr/logging/log.h>
#include <zephyr/net/net_if.h>
#include <zephyr/net/socket.h>

#include "transport.h"

LOG_MODULE_DECLARE(stream, LOG_LEVEL_INF);

static int sock = -1;
static struct net_if *usb_if;
static struct sockaddr_in6 peer;
static struct {
	uint32_t sent, down, errors;
	int last_errno;
} stats;

int transport_init(void)
{
	const struct device *ncm = DEVICE_DT_GET(DT_NODELABEL(cdc_ncm_eth0));

	usb_if = net_if_lookup_by_dev(ncm);
	if (usb_if == NULL) {
		LOG_ERR("udp: no USB network interface");
		return -ENODEV;
	}

	peer.sin6_family = AF_INET6;
	peer.sin6_port = htons(CONFIG_APP_RX_UDP_PORT);
	if (zsock_inet_pton(AF_INET6, CONFIG_APP_RX_UDP_PEER, &peer.sin6_addr) != 1) {
		LOG_ERR("udp: bad peer address %s", CONFIG_APP_RX_UDP_PEER);
		return -EINVAL;
	}
	/* Link-local and multicast peers need the interface as scope. */
	peer.sin6_scope_id = (uint32_t)net_if_get_by_iface(usb_if);

	sock = zsock_socket(AF_INET6, SOCK_DGRAM, IPPROTO_UDP);
	if (sock < 0) {
		LOG_ERR("udp: socket failed (%d)", errno);
		return -errno;
	}
	LOG_INF("udp: sending to [%s]:%d on interface %d", CONFIG_APP_RX_UDP_PEER,
		CONFIG_APP_RX_UDP_PORT, peer.sin6_scope_id);
	return 0;
}

int transport_send(const void *buf, size_t len)
{
	/* Admin up is set at boot; carrier means a host configured the link. */
	if (!net_if_is_carrier_ok(usb_if)) {
		/* No host yet: drop instead of queueing stale samples. */
		stats.down++;
		return 0;
	}
	if (zsock_sendto(sock, buf, len, 0, (struct sockaddr *)&peer, sizeof(peer)) < 0) {
		stats.errors++;
		stats.last_errno = errno;
		return -errno;
	}
	stats.sent++;
	return 0;
}

void transport_report(void)
{
	LOG_DBG("udp: %u sent, %u while down, %u errors (last %d)", stats.sent, stats.down,
		stats.errors, stats.last_errno);
	stats.sent = 0;
	stats.down = 0;
	stats.errors = 0;
}
```

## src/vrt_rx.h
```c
/*
 * SPDX-License-Identifier: GPL-3.0-or-later
 */

#ifndef STREAM_VRT_RX_H_
#define STREAM_VRT_RX_H_

#include <stdint.h>

#include <esp_sdr/esp_sdr.h>

/* One captured burst, handed from the capture core to the stream core. */
struct vrt_rx_burst {
	uint32_t seq;
	uint32_t count;
	uint64_t timestamp_ns;
	uint32_t freq_mhz;
	uint32_t rate_hz;
	int gain; /* ESP_SDR_RX_GAIN_AUTO or a fixed index */
	int32_t full_scale; /* 512 raw (10-bit), 32768 decimated */
	struct esp_sdr_iq16 iq[CONFIG_APP_RX_BURST_SAMPLES];
};

/* Smallest decimation: a decimated burst (16380 / m - 3 samples) must fit a burst. */
#define VRT_RX_DECIM_MIN 16U

/*
 * Receive stream rate and decimation, implemented by the capture side
 * (main.c): the capture rate (raw) or capture rate / m, VRT_RX_DECIM_MIN..160.
 */
int vrt_rx_set_rate(uint32_t hz);
uint32_t vrt_rx_get_rate(void);

/* Decimation algorithm applied at vrt_rx_set_rate()'s factor, m > 1. */
enum vrt_rx_decim {
	VRT_RX_DECIM_CIC,  /* low-pass + decimate: a clean narrowband signal, out-of-band dropped */
	VRT_RX_DECIM_FOLD, /* fold (decimate in frequency): full-band power estimate, aliased */
};

int vrt_rx_set_decim(enum vrt_rx_decim mode);
enum vrt_rx_decim vrt_rx_get_decim(void);

/* Signal data item size: 8, 12 or 16 bits (see iq_pack.h). */
int vrt_rx_set_bits(unsigned int bits);
unsigned int vrt_rx_get_bits(void);

int vrt_rx_init(void);
/* Called on the process core for every burst. */
void vrt_rx_burst(const struct vrt_rx_burst *b);
/* Called once per second after the statistics line. */
void vrt_rx_report(void);

#endif /* STREAM_VRT_RX_H_ */
```

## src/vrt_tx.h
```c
/*
 * SPDX-License-Identifier: GPL-3.0-or-later
 */

#ifndef STREAM_VRT_TX_H_
#define STREAM_VRT_TX_H_

#include <stdint.h>

struct vrt_tx_stats {
	uint32_t data;      /* signal data packets */
	uint32_t commands;  /* command packets */
	uint32_t acks;      /* acknowledges sent */
	uint32_t gaps;      /* packet counter discontinuities */
	uint32_t underruns; /* host fell behind the sample clock (paced backends) */
	uint32_t holes;     /* samples zero-filled where packets were missing (timestamps) */
	uint32_t late;      /* samples dropped as already passed (timestamps) */
	uint32_t bad;       /* undecodable datagrams */
	uint32_t errors;    /* backend or socket failures */
};

/* Open the UDP port and start the receive thread. */
int vrt_tx_init(void);
/* Packet and sample counters. */
void vrt_tx_get_stats(struct vrt_tx_stats *stats);
/* The transmit frequency and sample rate in use. */
void vrt_tx_get_settings(uint64_t *freq_hz, uint32_t *rate_hz);

#endif /* STREAM_VRT_TX_H_ */
```
